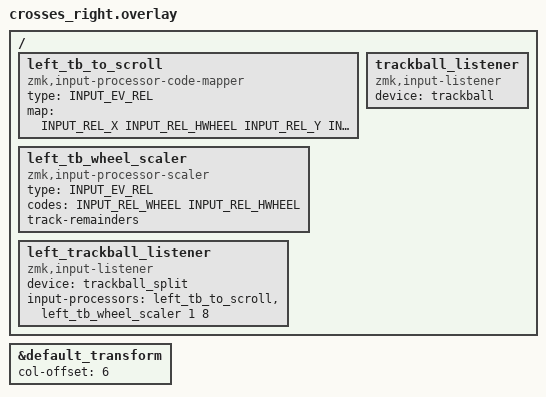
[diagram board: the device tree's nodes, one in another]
#include "crosses.dtsi"
#include <input/processors.dtsi>

&default_transform {
    col-offset = <6>;
};

/ {
    // Map REL_X → HWHEEL and REL_Y → WHEEL (full scroll in both axes).
    left_tb_to_scroll: left_tb_to_scroll {
        compatible = "zmk,input-processor-code-mapper";
        #input-processor-cells = <0>;
        type = <INPUT_EV_REL>;
        map = <INPUT_REL_X INPUT_REL_HWHEEL INPUT_REL_Y INPUT_REL_WHEEL>;
    };

    // Scale down wheel events. track-remainders accumulates sub-threshold
    // counts across polls rather than dropping them, preventing choppy scroll.
    left_tb_wheel_scaler: left_tb_wheel_scaler {
        compatible = "zmk,input-processor-scaler";
        #input-processor-cells = <2>;
        type = <INPUT_EV_REL>;
        codes = <INPUT_REL_WHEEL INPUT_REL_HWHEEL>;
        track-remainders;
    };

    trackball_listener {
        compatible = "zmk,input-listener";
        device = <&trackball>;
    };

    left_trackball_listener {
        compatible = "zmk,input-listener";
        device = <&trackball_split>;
        input-processors = <&left_tb_to_scroll>, <&left_tb_wheel_scaler 1 8>;
    };
};
